# CH585SFR register map
Vendor: WCH Ltd.; Series: CH58x; File version: 1.0
CPU: RISC-V r0p0, little endian, no MPU, no FPU, 2 interrupt priority bits
Registers are 8-bit, Read or Write, reset 0x0 unless marked. A register's access mark holds for its fields unless they carry their own. Offsets are from the block's base; [hi:lo] are bit positions.

## SPI0
Base 0x40004000
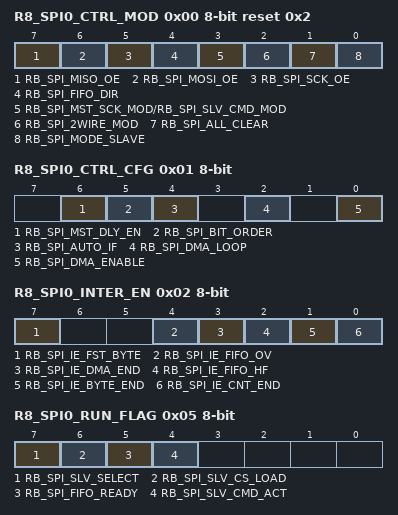
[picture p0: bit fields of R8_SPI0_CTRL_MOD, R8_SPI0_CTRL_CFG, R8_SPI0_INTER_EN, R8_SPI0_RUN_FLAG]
0x00 R8_SPI0_CTRL_MOD reset 0x2 — RW, SPI0 mode control
  [7] RB_SPI_MISO_OE — RW, SPI MISO output enable
  [6] RB_SPI_MOSI_OE — RW, SPI MOSI output enable
  [5] RB_SPI_SCK_OE — RW, SPI SCK output enable
  [4] RB_SPI_FIFO_DIR — RW, SPI FIFO direction: 0=out(write @master mode), 1=in(read @master mode)
  [3] RB_SPI_MST_SCK_MOD/RB_SPI_SLV_CMD_MOD — RW, SPI master clock mode: 0=mode 0, 1=mode 3;RW, SPI0 slave command mode: 0=byte stream, 1=first byte command
  [2] RB_SPI_2WIRE_MOD — RW, SPI0 enable 2 wire mode for slave: 0=3wire(SCK0,MOSI,MISO), 1=2wire(SCK0,MISO=MXSX)
  [1] RB_SPI_ALL_CLEAR — RW, force clear SPI FIFO and count
  [0] RB_SPI_MODE_SLAVE — RW, SPI0 slave mode: 0=master or host, 1=slave or device
0x01 R8_SPI0_CTRL_CFG — RW, SPI0 configuration control
  [6] RB_SPI_MST_DLY_EN — RW, SPI master input delay enable
  [5] RB_SPI_BIT_ORDER — RW, SPI bit data order: 0=MSB first, 1=LSB first
  [4] RB_SPI_AUTO_IF — RW, enable buffer/FIFO accessing to auto clear RB_SPI_IF_BYTE_END interrupt flag
  [2] RB_SPI_DMA_LOOP — RW, SPI0 DMA address loop enable
  [0] RB_SPI_DMA_ENABLE — RW, SPI0 DMA enable
0x02 R8_SPI0_INTER_EN — RW, SPI0 interrupt enable
  [7] RB_SPI_IE_FST_BYTE — RW, enable interrupt for SPI0 slave mode first byte received
  [4] RB_SPI_IE_FIFO_OV — RW, enable interrupt for SPI0 FIFO overflow
  [3] RB_SPI_IE_DMA_END — RW, enable interrupt for SPI0 DMA completion
  [2] RB_SPI_IE_FIFO_HF — RW, enable interrupt for SPI FIFO half
  [1] RB_SPI_IE_BYTE_END — RW, enable interrupt for SPI byte exchanged
  [0] RB_SPI_IE_CNT_END — RW, enable interrupt for SPI total byte count end
0x03 R8_SPI0_CLOCK_DIV/R8_SPI0_SLAVE_PRE reset 0x10 — RW, SPI0 master clock divisor;RW, SPI0 slave preset value
0x04 R8_SPI0_BUFFER reset not defined — RW, SPI0 data buffer
0x05 R8_SPI0_RUN_FLAG ro — RO, SPI0 work flag
  [7] RB_SPI_SLV_SELECT — RO, SPI0 slave selection status
  [6] RB_SPI_SLV_CS_LOAD — RO, SPI0 slave chip-select loading status
  [5] RB_SPI_FIFO_READY — RO, SPI FIFO ready status
  [4] RB_SPI_SLV_CMD_ACT — RO, SPI0 slave first byte or command flag
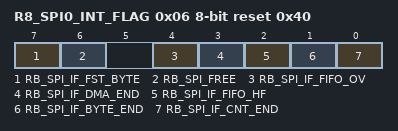
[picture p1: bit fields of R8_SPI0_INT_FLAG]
0x06 R8_SPI0_INT_FLAG reset 0x40 — RW1, SPI0 interrupt flag
  [7] RB_SPI_IF_FST_BYTE — RW1, interrupt flag for SPI0 slave mode first byte received
  [6] RB_SPI_FREE — RO, current SPI free status
  [4] RB_SPI_IF_FIFO_OV — RW1, interrupt flag for SPI0 FIFO overflow
  [3] RB_SPI_IF_DMA_END — RW1, interrupt flag for SPI0 DMA completion
  [2] RB_SPI_IF_FIFO_HF — RW1, interrupt flag for SPI FIFO half
  [1] RB_SPI_IF_BYTE_END — RW1, interrupt flag for SPI byte exchanged
  [0] RB_SPI_IF_CNT_END — RW1, interrupt flag for SPI total byte count end
0x07 R8_SPI0_FIFO_COUNT — RW, SPI0 FIFO count status
  [3:0] R8_SPI0_FIFO_COUNT
0x0C R16_SPI0_TOTAL_CNT 16-bit — RW, SPI0 total byte count, only low 12 bit
  [11:0] R16_SPI0_TOTAL_CNT
0x10 R8_SPI0_FIFO reset not defined — RO/WO, SPI0 FIFO register
0x13 R8_SPI0_FIFO_COUNT1 ro — RO, SPI0 FIFO count status
0x14 R32_SPI0_DMA_NOW 32-bit reset not defined — RW, SPI0 DMA current address
  [16:0] RB_SPI0_DMA_NOW
0x18 R32_SPI0_DMA_BEG 32-bit reset not defined — RW, SPI0 DMA begin address
  [16:0] R32_SPI0_DMA_BEG
0x1C R32_SPI0_DMA_END 32-bit reset not defined — RW, SPI0 DMA end address
  [16:0] R32_SPI0_DMA_END

## SPI1
Base 0x40004400
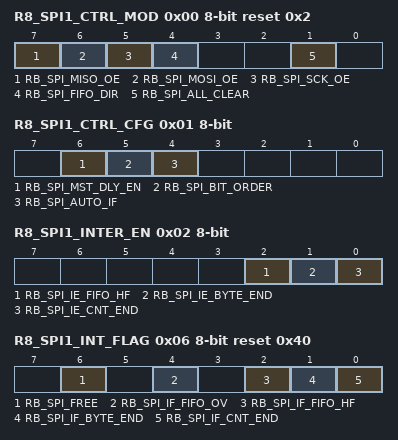
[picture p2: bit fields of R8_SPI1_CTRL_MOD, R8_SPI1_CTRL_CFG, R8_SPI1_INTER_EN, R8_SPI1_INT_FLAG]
0x00 R8_SPI1_CTRL_MOD reset 0x2 — RW, SPI1 mode control
  [7] RB_SPI_MISO_OE — RW, SPI MISO output enable
  [6] RB_SPI_MOSI_OE — RW, SPI MOSI output enable
  [5] RB_SPI_SCK_OE — RW, SPI SCK output enable
  [4] RB_SPI_FIFO_DIR — RW, SPI FIFO direction: 0=out(write @master mode), 1=in(read @master mode)
  [1] RB_SPI_ALL_CLEAR — RW, force clear SPI FIFO and count
0x01 R8_SPI1_CTRL_CFG — RW, SPI1 configuration control
  [6] RB_SPI_MST_DLY_EN — RW, SPI master input delay enable
  [5] RB_SPI_BIT_ORDER — RW, SPI bit data order: 0=MSB first, 1=LSB first
  [4] RB_SPI_AUTO_IF — RW, enable buffer/FIFO accessing to auto clear RB_SPI_IF_BYTE_END interrupt flag
0x02 R8_SPI1_INTER_EN — RW, SPI0 interrupt enable
  [2] RB_SPI_IE_FIFO_HF — RW, enable interrupt for SPI FIFO half
  [1] RB_SPI_IE_BYTE_END — RW, enable interrupt for SPI byte exchanged
  [0] RB_SPI_IE_CNT_END — RW, enable interrupt for SPI total byte count end
0x03 R8_SPI1_CLOCK_DIV reset 0x10 — RW, SPI1 master clock divisor;RW, SPI1 slave preset value
0x04 R8_SPI1_BUFFER reset not defined — RW, SPI1 data buffer
0x05 R8_SPI1_RUN_FLAG ro — RO, SPI1 work flag
  [5] RB_SPI_FIFO_READY — RO, SPI FIFO ready status
0x06 R8_SPI1_INT_FLAG reset 0x40 — RW1, SPI1 interrupt flag
  [6] RB_SPI_FREE — RO, current SPI free status
  [4] RB_SPI_IF_FIFO_OV — RW1, interrupt flag for SPI1 FIFO overflow
  [2] RB_SPI_IF_FIFO_HF — RW1, interrupt flag for SPI FIFO half
  [1] RB_SPI_IF_BYTE_END — RW1, interrupt flag for SPI byte exchanged
  [0] RB_SPI_IF_CNT_END — RW1, interrupt flag for SPI total byte count end
0x07 R8_SPI1_FIFO_COUNT — RW, SPI1 FIFO count status
  [3:0] R8_SPI1_FIFO_COUNT
0x0C R16_SPI1_TOTAL_CNT 16-bit — RW, SPI1 total byte count, only low 12 bit
  [11:0] R16_SPI1_TOTAL_CNT
0x10 R8_SPI1_FIFO reset not defined — RO/WO, SPI1 FIFO register
0x13 R8_SPI1_FIFO_COUNT1 ro — RO, SPI1 FIFO count status
